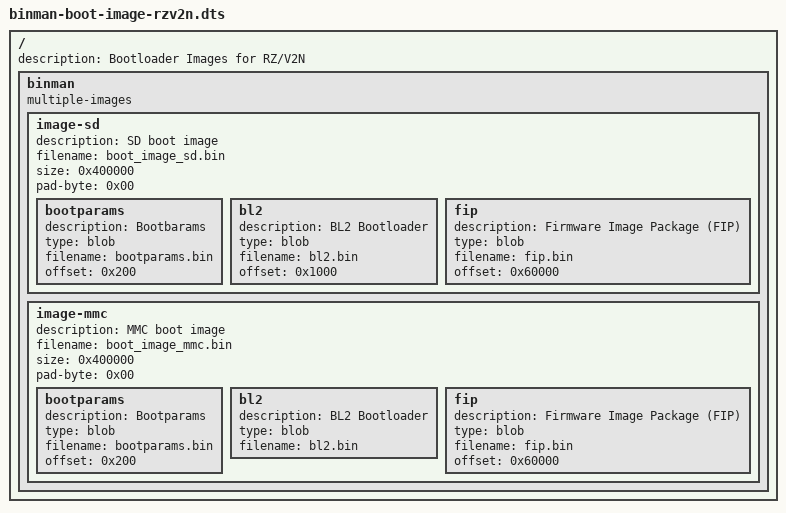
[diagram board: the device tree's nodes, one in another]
/dts-v1/;

/ {
	description = "Bootloader Images for RZ/V2N";
	#address-cells = <1>;
	binman {
		multiple-images;
		image-sd {
			description = "SD boot image";
			filename = "boot_image_sd.bin";
			size = <0x400000>; // 4MB total size
			pad-byte = <0x00>; // Padding byte

			bootparams {
				description = "Bootbarams";
				type = "blob";
				filename = "bootparams.bin";
				offset = <0x200>;
			};

			bl2 {
				description = "BL2 Bootloader";
				type = "blob";
				filename = "bl2.bin";
				offset = <0x1000>;
			};

			fip {
				description = "Firmware Image Package (FIP)";
				type = "blob";
				filename = "fip.bin";
				// RZ/V2N FIP base: ATF RZV2N_FIP_OFFSET = RZV2N_BL2_SIZE_MAX
				// (BOOT_TFA_USING_CM33=0). BL2 reads the FIP from this offset.
				offset = <0x60000>;
			};
		};
		image-mmc {
			description = "MMC boot image";
			filename = "boot_image_mmc.bin";
			size = <0x400000>; // 4MB total size
			pad-byte = <0x00>; // Padding byte

			bootparams {
				description = "Bootparams";
				type = "blob";
				filename = "bootparams.bin";
				offset = <0x200>;
			};

			bl2 {
				description = "BL2 Bootloader";
				type = "blob";
				filename = "bl2.bin";
			};

			fip {
				description = "Firmware Image Package (FIP)";
				type = "blob";
				filename = "fip.bin";
				// RZ/V2N FIP base: ATF RZV2N_FIP_OFFSET = RZV2N_BL2_SIZE_MAX
				// (BOOT_TFA_USING_CM33=0). BL2 reads the FIP from this offset.
				offset = <0x60000>;
			};
		};
	};
};
